# STM32U5Gx register map
File version: 1.0
CPU: CM33 r0p1, little endian, MPU, FPU, 4 interrupt priority bits
Registers are 32-bit, read-write, reset 0x0 unless marked. A register's access mark holds for its fields unless they carry their own. Offsets are from the block's base; [hi:lo] are bit positions.

## USART1 — Universal synchronous asynchronous receiver transmitter
Base 0x40013800
Same registers: USART2 0x40004400, USART3 0x40004800, UART4 0x40004C00, UART5 0x40005000, USART6 0x40006400, SEC_USART2 0x50004400, SEC_USART3 0x50004800, SEC_UART4 0x50004C00, SEC_UART5 0x50005000, SEC_USART6 0x50006400, SEC_USART1 0x50013800
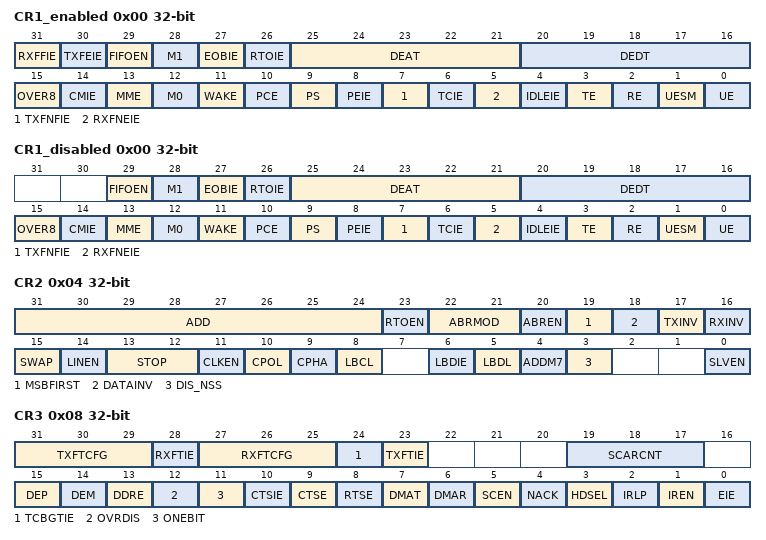
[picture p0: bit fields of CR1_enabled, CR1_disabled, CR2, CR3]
0x00 CR1_enabled — Control register 1
  [31] RXFFIE
  [30] TXFEIE
  [29] FIFOEN
  [28] M1 — Word length
  [27] EOBIE — End of Block interruptenable
  [26] RTOIE — Receiver timeout interrupt
  [25:21] DEAT
  [20:16] DEDT
  [15] OVER8 — Oversampling mode
  [14] CMIE — Character match interrupt enable
  [13] MME — Mute mode enable
  [12] M0 — Word length
  [11] WAKE — Receiver wakeup method
  [10] PCE — Parity control enable
  [9] PS — Parity selection
  [8] PEIE — PE interrupt enable
  [7] TXFNFIE — TXFIFO not full interrupt enable
  [6] TCIE — Transmission complete interrupt enable
  [5] RXFNEIE — RXFIFO not empty interrupt enable
  [4] IDLEIE — IDLE interrupt enable
  [3] TE — Transmitter enable
  [2] RE — Receiver enable
  [1] UESM — USART enable in Stop mode
  [0] UE — USART enable
0x00 CR1_disabled (alternate view of CR1_enabled) — Control register 1
  [29] FIFOEN
  [28] M1 — Word length
  [27] EOBIE — End of Block interrupt enable
  [26] RTOIE — Receiver timeout interrupt enable
  [25:21] DEAT
  [20:16] DEDT
  [15] OVER8 — Oversampling mode
  [14] CMIE — Character match interrupt enable
  [13] MME — Mute mode enable
  [12] M0 — Word length
  [11] WAKE — Receiver wakeup method
  [10] PCE — Parity control enable
  [9] PS — Parity selection
  [8] PEIE — PE interrupt enable
  [7] TXFNFIE — TXFIFO not full interrupt enable
  [6] TCIE — Transmission complete interrupt enable
  [5] RXFNEIE — RXFIFO not empty interrupt enable
  [4] IDLEIE — IDLE interrupt enable
  [3] TE — Transmitter enable
  [2] RE — Receiver enable
  [1] UESM — USART enable in Stop mode
  [0] UE — USART enable
0x04 CR2 — Control register 2
  [31:24] ADD — Address of the USART node
  [23] RTOEN — Receiver timeout enable
  [22:21] ABRMOD — Auto baud rate mode
  [20] ABREN — Auto baud rate enable
  [19] MSBFIRST — Most significant bit first
  [18] DATAINV — Binary data inversion
  [17] TXINV — TX pin active level inversion
  [16] RXINV — RX pin active level inversion
  [15] SWAP — Swap TX/RX pins
  [14] LINEN — LIN mode enable
  [13:12] STOP — STOP bits
  [11] CLKEN — Clock enable
  [10] CPOL — Clock polarity
  [9] CPHA — Clock phase
  [8] LBCL — Last bit clock pulse
  [6] LBDIE — LIN break detection interrupt enable
  [5] LBDL — LIN break detection length
  [4] ADDM7 — 7-bit Address Detection/4-bit Address Detection
  [3] DIS_NSS
  [0] SLVEN
0x08 CR3 — Control register 3
  [31:29] TXFTCFG
  [28] RXFTIE
  [27:25] RXFTCFG
  [24] TCBGTIE
  [23] TXFTIE
  [19:17] SCARCNT — Smartcard auto-retry count
  [15] DEP — Driver enable polarity selection
  [14] DEM — Driver enable mode
  [13] DDRE — DMA Disable on Reception Error
  [12] OVRDIS — Overrun Disable
  [11] ONEBIT — One sample bit method enable
  [10] CTSIE — CTS interrupt enable
  [9] CTSE — CTS enable
  [8] RTSE — RTS enable
  [7] DMAT — DMA enable transmitter
  [6] DMAR — DMA enable receiver
  [5] SCEN — Smartcard mode enable
  [4] NACK — Smartcard NACK enable
  [3] HDSEL — Half-duplex selection
  [2] IRLP — Ir low-power
  [1] IREN — Ir mode enable
  [0] EIE — Error interrupt enable
0x0C BRR — Baud rate register
  [15:0] BRR
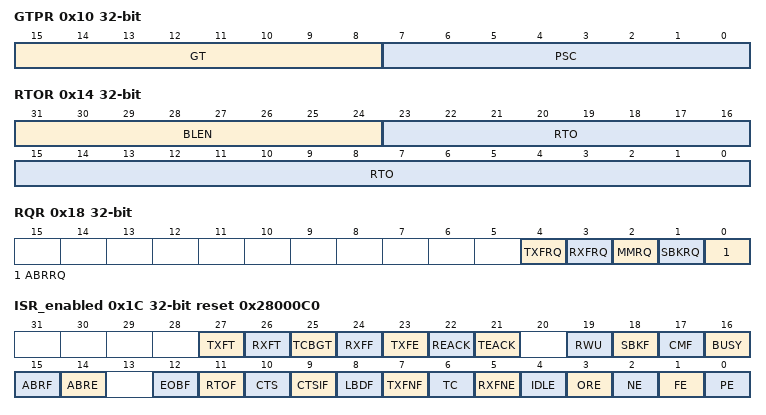
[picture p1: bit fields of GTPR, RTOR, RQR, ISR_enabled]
0x10 GTPR — Guard time and prescaler register
  [15:8] GT — Guard time value
  [7:0] PSC — Prescaler value
0x14 RTOR — Receiver timeout register
  [31:24] BLEN — Block Length
  [23:0] RTO — Receiver timeout value
0x18 RQR wo — Request register
  [4] TXFRQ — Transmit data flush request
  [3] RXFRQ — Receive data flush request
  [2] MMRQ — Mute mode request
  [1] SBKRQ — Send break request
  [0] ABRRQ — Auto baud rate request
0x1C ISR_enabled ro reset 0x28000C0 — Interrupt & status register
  [27] TXFT, [26] RXFT, [25] TCBGT, [24] RXFF, [23] TXFE, [22] REACK, [21] TEACK, [19] RWU, [18] SBKF, [17] CMF, [16] BUSY, [15] ABRF, [14] ABRE, [12] EOBF, [11] RTOF, [10] CTS, [9] CTSIF, [8] LBDF, [7] TXFNF, [6] TC, [5] RXFNE, [4] IDLE, [3] ORE, [2] NE, [1] FE, [0] PE
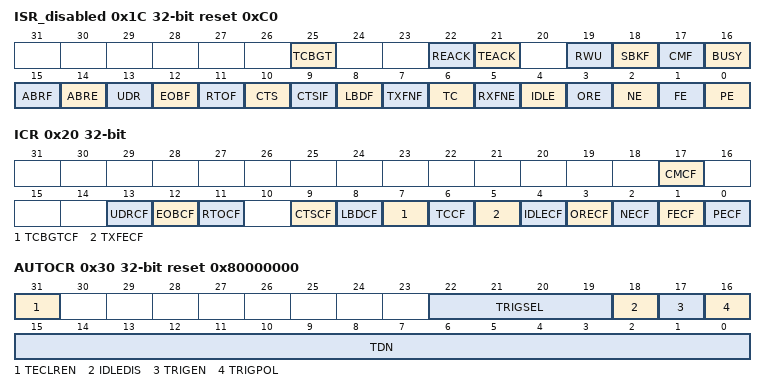
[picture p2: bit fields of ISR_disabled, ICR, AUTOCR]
0x1C ISR_disabled ro reset 0xC0 (alternate view of ISR_enabled) — Interrupt & status register
  [25] TCBGT, [22] REACK, [21] TEACK, [19] RWU, [18] SBKF, [17] CMF, [16] BUSY, [15] ABRF, [14] ABRE, [13] UDR, [12] EOBF, [11] RTOF, [10] CTS, [9] CTSIF, [8] LBDF, [7] TXFNF, [6] TC, [5] RXFNE, [4] IDLE, [3] ORE, [2] NE, [1] FE, [0] PE
0x20 ICR wo — Interrupt flag clear register
  [17] CMCF — Character match clear flag
  [13] UDRCF
  [12] EOBCF — End of block clear flag
  [11] RTOCF — Receiver timeout clear flag
  [9] CTSCF — CTS clear flag
  [8] LBDCF — LIN break detection clear flag
  [7] TCBGTCF
  [6] TCCF — Transmission complete clear flag
  [5] TXFECF
  [4] IDLECF — Idle line detected clear flag
  [3] ORECF — Overrun error clear flag
  [2] NECF — Noise detected clear flag
  [1] FECF — Framing error clear flag
  [0] PECF — Parity error clear flag
0x24 RDR ro — Receive data register
  [8:0] RDR — Receive data value
0x28 TDR — Transmit data register
  [8:0] TDR — Transmit data value
0x2C PRESC
  [3:0] PRESCALER
0x30 AUTOCR reset 0x80000000
  [31] TECLREN
  [22:19] TRIGSEL
  [18] IDLEDIS
  [17] TRIGEN
  [16] TRIGPOL — TRIPOL
  [15:0] TDN
